# Spirit3 register map
File version: 1.0
CPU: CM0+ r0p0, little endian, no MPU, no FPU, 2 interrupt priority bits
Registers are 32-bit, read-write, reset 0x0 unless marked. A register's access mark holds for its fields unless they carry their own. Offsets are from the block's base; lines under a group give offsets from that group; [hi:lo] are bit positions; {n}, {i} and the like mark numbered series; 'fields as' and 'values as' point back to an identical list; <NAME> marks a mode.

## Memory map
0x40000000 SYSCFG size 0x40 — System configuration controller
0x40001000 FLASH size 0x90
0x40002000 TIM2 size 0x400 — General-purpose-timers
0x40003000 IWDG size 0x400 — Independent watchdog
0x40004000 RTC size 0x400 — Real-time clock
0x40005000 TIM16 size 0x400 — General-purpose-timers
0x40007000 LCD size 0x400 — Liquid crystal display controller
0x40009000 COMP size 0x9 — Comparator instance 1
0x41000000 I2C1 size 0x400 — Inter-integrated circuit
0x41001000 I2C2 size 0x400
0x41002000 SPI1 size 0x400 — Serial peripheral interface/Inter-IC sound
0x41004000 USART1 size 0x3FF — Universal synchronous asynchronous receiver transmitter
0x41005000 LPUART1 size 0x400 — Universal synchronous asynchronous receiver transmitter
0x41006000 ADC size 0x400
0x41007000 SPI3 size 0x400
0x48000000 GPIOA size 0x400 — General-purpose I/Os
0x48100000 GPIOB size 0x400 — General-purpose I/Os
0x48200000 CRC size 0x400 — Cyclic redundancy check calculation unit
0x48400000 RCC size 0xFFFF — Reset and clock control
0x48500000 PWR size 0x400 — Power control
0x48600000 RNG size 0x400 — Random number generator
0x48700000 DMA size 0x400 — Direct memory access controller
0x48800000 DMAMUX size 0x400 — Direct memory access Multiplexer
0x48900000 AES1 size 0x400 — Advanced encryption standard hardware accelerator 1
0x49000000 MR_SUBG size 0x1000
0x49001000 BUBBLE_RF size 0x1000

## Interrupts
0 FLASH — NVM interrupt
1 RCC — RCC interrupt
3 I2C1 — I2C1 interrurpt
4 I2C2 — I2C2 interrupt
5 SPI1 — SPI1 interrupt
7 SPI3 — SPI3 interrupt
8 USART1 — USART interrupt
9 LPUART (LPUART1) — Low Power UART interrupt
10 TIM2 — TIM2 global interrupt
11 RTC — RTC interrupt
12 ADC — ADC interrupt
13 AES1 — AES1 global interrupt
15 GPIOA — GPIOA interrupt
16 GPIOB — GPIOB interrupt
17 DMA — DMA interrupt
18 BUBBLE (BUBBLE_RF) — Bubble interrupt
19 COMP — COMP1 interrupt through AIEC[21:20]
20 MR_SUBG_BUSY (MR_SUBG) — MR_SUBG Busy interrupt
21 MR_SUBG — MR_SUBG interrupt
22 TX_RX_SEQUENCE (MR_SUBG) — MR_SUBG TX/RX Sequence interrupt
23 CPU_WKUP (MR_SUBG) — CPU Wakeup interrupt
24 SUBG_WKUP (MR_SUBG) — SUBG Wakeup interrupt
26 TIM16 — TIM16 global interrupt
27 LCD — LCD global interrupt

## AES1 — Advanced encryption standard hardware accelerator 1
Base 0x48900000
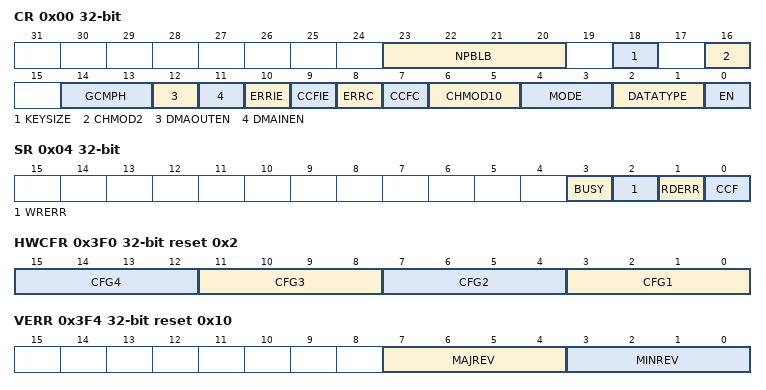
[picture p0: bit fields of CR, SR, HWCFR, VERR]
0x00 CR — control register
  [23:20] NPBLB — Number of padding bytes in last block of payload
  [18] KEYSIZE — Key size selection
  [16] CHMOD2 — AES chaining mode Bit2
  [14:13] GCMPH — Used only for GCM, CCM and GMAC algorithms and has no effect when other algorithms are selected
  [12] DMAOUTEN — Enable DMA management of data output phase
  [11] DMAINEN — Enable DMA management of data input phase
  [10] ERRIE — Error interrupt enable
  [9] CCFIE — CCF flag interrupt enable
  [8] ERRC — Error clear
  [7] CCFC — Computation Complete Flag Clear
  [6:5] CHMOD10 — AES chaining mode Bit1 Bit0
  [4:3] MODE — AES operating mode
  [2:1] DATATYPE — Data type selection (for data in and data out to/from the cryptographic block)
  [0] EN — AES enable
0x04 SR ro — status register
  [3] BUSY — Busy flag
  [2] WRERR — Write error flag
  [1] RDERR — Read error flag
  [0] CCF — Computation complete flag
0x08 DINR — data input register
  [31:0] AES_DINR — Data Input Register
0x0C DOUTR ro — data output register
  [31:0] AES_DOUTR — Data output register
0x10 KEYR0 — key register 0
  [31:0] AES_KEYR0 — Data Output Register (LSB key [31:0])
0x14 KEYR1 — key register 1
  [31:0] AES_KEYR1 — AES key register (key [63:32])
0x18 KEYR2 — key register 2
  [31:0] AES_KEYR2 — AES key register (key [95:64])
0x1C KEYR3 — key register 3
  [31:0] AES_KEYR3 — AES key register (MSB key [127:96])
0x20 IVR0 — initialization vector register 0
  [31:0] AES_IVR0 — initialization vector register (LSB IVR [31:0])
0x24 IVR1 — initialization vector register 1
  [31:0] AES_IVR1 — Initialization Vector Register (IVR [63:32])
0x28 IVR2 — initialization vector register 2
  [31:0] AES_IVR2 — Initialization Vector Register (IVR [95:64])
0x2C IVR3 — initialization vector register 3
  [31:0] AES_IVR3 — Initialization Vector Register (MSB IVR [127:96])
{0x20+4i} KEYR{i} (i=4..7) — key register {i}
  [31:0] AES_KEYR{i} — AES key register (MSB key [{32i+31}:{32i}])
{0x40+4i} SUSP{i}R (i=0..7) — AES suspend register {i}
  [31:0] AES_SUSP{i}R
0x3F0 HWCFR ro reset 0x2 — AES hardware configuration register
  [4n-1:4n-4] CFG{n} (n=1..4) — HW Generic {n}
0x3F4 VERR ro reset 0x10 — AES version register
  [7:4] MAJREV — Major revision
  [3:0] MINREV — Minor revision
0x3F8 IPIDR ro reset 0x170023 — AES identification register
  [31:0] ID — Identification code
0x3FC SIDR ro reset 0xA3C5DD01 — AES size ID register
  [31:0] SID — Size Identification code
